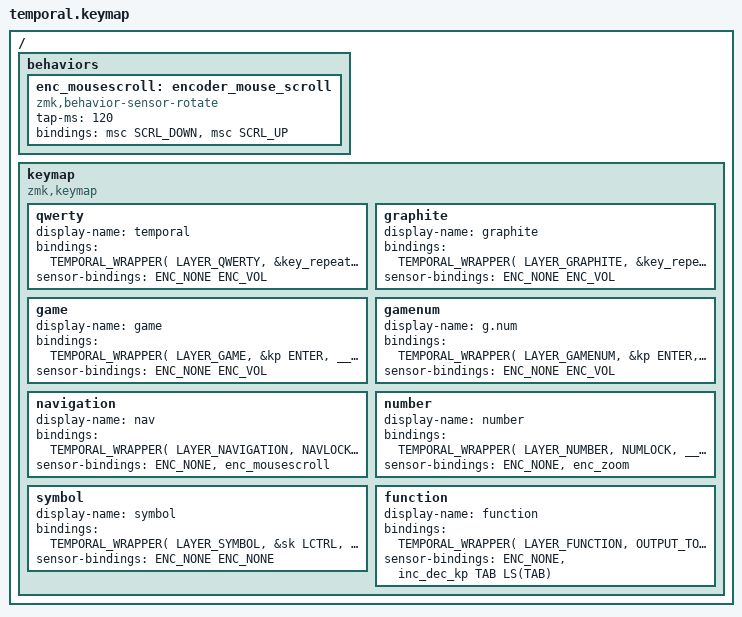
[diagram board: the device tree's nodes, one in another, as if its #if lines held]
#include "temporal.h"
#include "t4corun/t4corun.keymap"

/*
 * Only builds whose shield overlay included boards/shields/temporal/trackpad.dtsi
 * (temporal_prospector, temporal_prospectorright) define this macro.
 */
#ifdef TEMPORAL_TRACKPAD_DTSI
#include "t4corun/trackpad.dtsi"
#endif

/ {
    behaviors {
        MOD_TAP_MACRO(zoom_in,  LCTRL,     EQUAL, 30, 10)
        MOD_TAP_MACRO(zoom_out, LCTRL,     MINUS, 30, 10)

        ROTATE_MACRO(enc_zoom,  &zoom_in,  &zoom_out, 30)

        enc_mousescroll: encoder_mouse_scroll {
            compatible = "zmk,behavior-sensor-rotate";
            #sensor-binding-cells = <0>;
            tap-ms = <120>;
            bindings = <&msc SCRL_DOWN>, <&msc SCRL_UP>;
        };
    };
};

/ {
    keymap {
        compatible = "zmk,keymap";

        qwerty {
            display-name = "temporal";
            bindings = <
                /* See temporal.h for postitions   */
                /* Main 3x5x3, LH3, RH3,           */
				/* LH3 is the left most thumb key  */
                /* RH3 is the rotary encoder click */
                TEMPORAL_WRAPPER(
                    LAYER_QWERTY,					
                    &key_repeat,
                    ____xx____
                )
            >;

            sensor-bindings = <
                ENC_NONE
                ENC_VOL
            >;
        };

        graphite {
            display-name = "graphite";
            bindings = <
                TEMPORAL_WRAPPER(
                    LAYER_GRAPHITE,
                    &key_repeat,
                    ____xx____
                )
            >;

            sensor-bindings = <
                ENC_NONE
                ENC_VOL
            >;
        };

        game {
            display-name = "game";
            bindings = <
                TEMPORAL_WRAPPER(
                    LAYER_GAME,
                    &kp ENTER,
                    ____xx____
                )
            >;

            sensor-bindings = <
                ENC_NONE
                ENC_VOL
            >;
        };

        gamenum {
            display-name = "g.num";
            bindings = <
                TEMPORAL_WRAPPER(
                    LAYER_GAMENUM,
                    &kp ENTER,
                    ____xx____
                )
            >;

            sensor-bindings = <
                ENC_NONE
                ENC_VOL
            >;
        };

        navigation {
            display-name = "nav";
            bindings = <
                TEMPORAL_WRAPPER(
                    LAYER_NAVIGATION,
                    NAVLOCK,
                    ____xx____
                )
            >;

            sensor-bindings = <
                ENC_NONE
                &enc_mousescroll
            >;
        };

        number {
            display-name = "number";
            bindings = <
                TEMPORAL_WRAPPER(
                    LAYER_NUMBER,
                    NUMLOCK,
                    ____xx____
                )
            >;

            sensor-bindings = <
                ENC_NONE
                &enc_zoom
            >;
        };

        symbol {
            display-name = "symbol";
            bindings = <
                TEMPORAL_WRAPPER(
                    LAYER_SYMBOL,
                    &sk LCTRL,
                    ____xx____
                )
            >;

            sensor-bindings = <
                ENC_NONE
                ENC_NONE
            >;
        };

        function {
            display-name = "function";
            bindings = <
                TEMPORAL_WRAPPER(
                    LAYER_FUNCTION,
                    OUTPUT_TOG,
                    ____xx____
                )
            >;

            sensor-bindings = <
                ENC_NONE
                &inc_dec_kp TAB LS(TAB)
            >;
        };
    };
};
